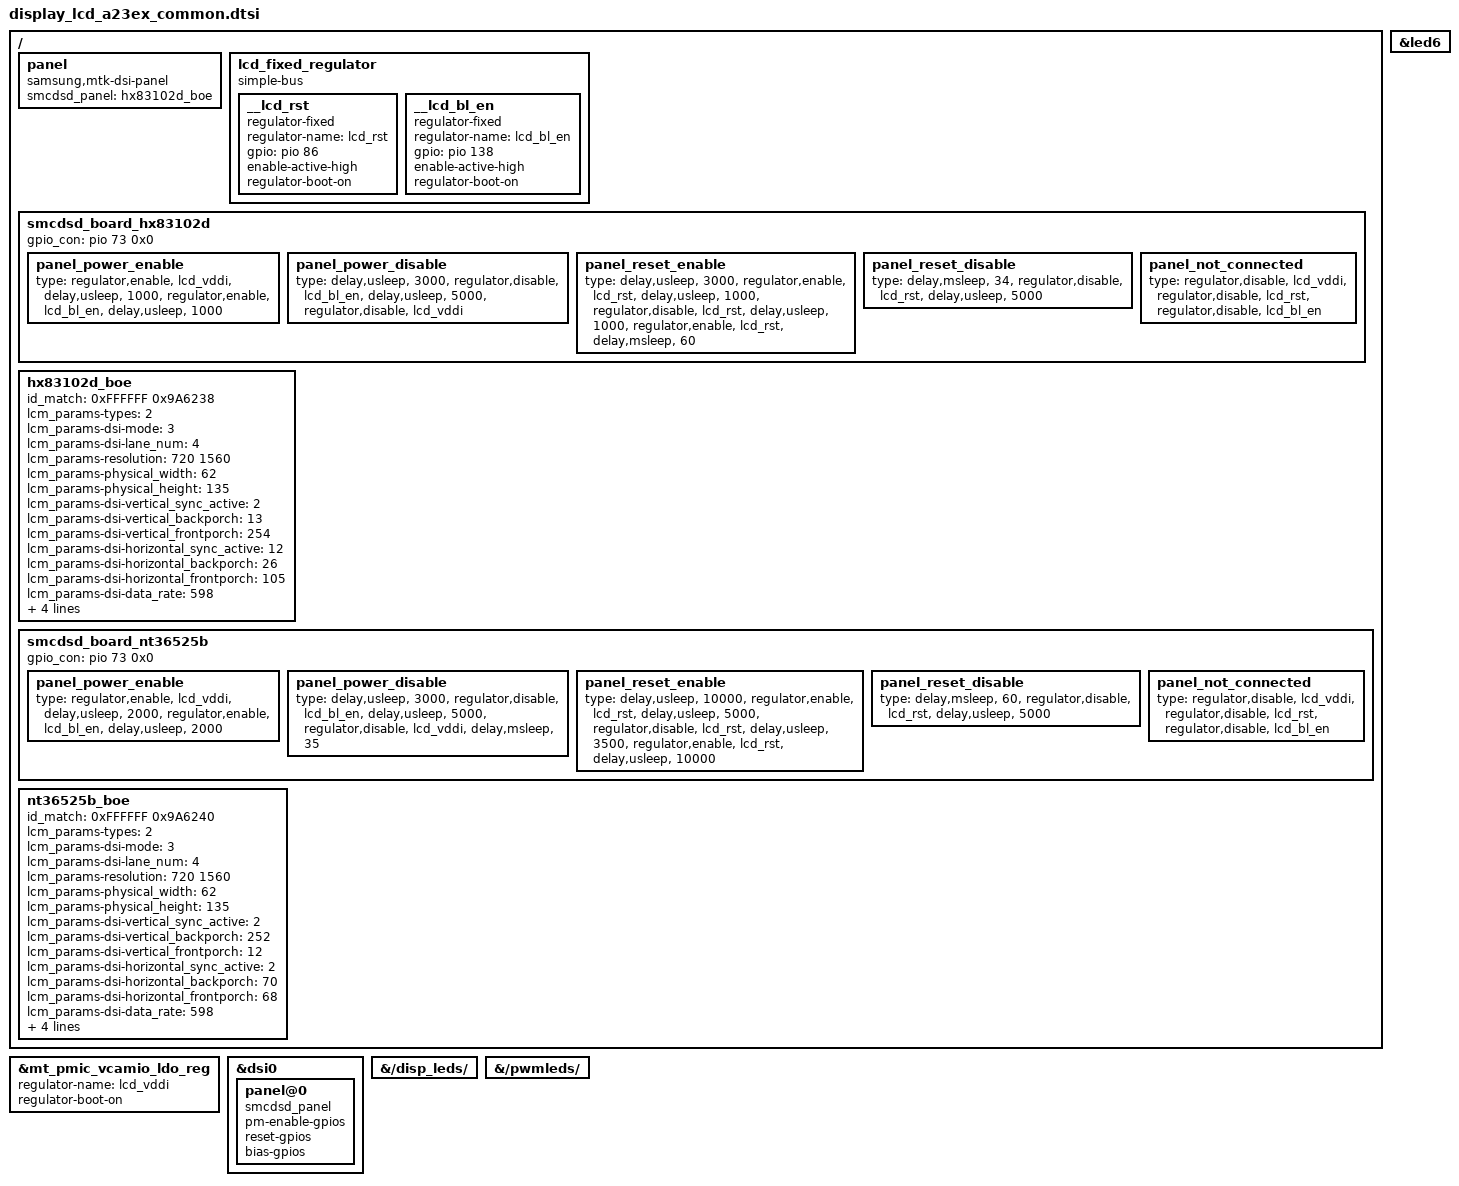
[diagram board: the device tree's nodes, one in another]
/*
 * SAMSUNG LCD Panel Device Tree Source
 *
 * Copyright (c) Samsung Electronics Co., Ltd.
 *		http://www.samsung.com
 *
 * This program is free software; you can redistribute it and/or modify
 * it under the terms of the GNU General Public License version 2 as
 * published by the Free Software Foundation.
 */

/ {
	fragment@led {
		target-path = "/disp_leds/";
		__overlay__ {
			compatible;
		};
	};

	fragment@pwm {
		target-path = "/pwmleds/";
		__overlay__ {
			compatible;
		};
	};

	fragment@lcd {
		target-path = "/";
		__overlay__ {
			panel {
				compatible = "samsung,mtk-dsi-panel";
				smcdsd_panel = <&hx83102d_boe>;
			};

			lcd_fixed_regulator: lcd_fixed_regulator {
				compatible = "simple-bus";

				__lcd_rst: __lcd_rst {
					compatible = "regulator-fixed";
					regulator-name = "lcd_rst";
					gpio = <&pio 86 0>;	/* LCD_RST */
					enable-active-high;
					regulator-boot-on;
				};
				__lcd_bl_en: __lcd_bl_en {
					compatible = "regulator-fixed";
					regulator-name = "lcd_bl_en";
					gpio = <&pio 138 0>;	/* LCD_BL_EN */
					enable-active-high;
					regulator-boot-on;
				};
			};

			smcdsd_board_hx83102d: smcdsd_board_hx83102d {
				//gpio_det = <&pio 6 0x1>;	/* LCD_BC_CTRL */
				gpio_con = <&pio 73 0x0>;	/* LCD_CON_DET */

				panel_power_enable {
					type =
					"regulator,enable",	"lcd_vddi",
					"delay,usleep",	"1000",
					"regulator,enable",	"lcd_bl_en",
					"delay,usleep",	"1000";
				};
				panel_power_disable {
					type =
					"delay,usleep",	"3000",
					"regulator,disable",	"lcd_bl_en",
					"delay,usleep",	"5000",
					"regulator,disable",	"lcd_vddi";
				};
				panel_reset_enable {
					type =
					"delay,usleep",	"3000",
					"regulator,enable",	"lcd_rst",
					"delay,usleep",	"1000",
					"regulator,disable",	"lcd_rst",
					"delay,usleep",	"1000",
					"regulator,enable",	"lcd_rst",
					"delay,msleep",	"60";
				};
				panel_reset_disable {
					type =
					"delay,msleep",	"34",
					"regulator,disable",	"lcd_rst",
					"delay,usleep",	"5000";
				};
				panel_not_connected {
					type =
					"regulator,disable",	"lcd_vddi",
					"regulator,disable",	"lcd_rst",
					"regulator,disable",	"lcd_bl_en";
				};
			};

			hx83102d_boe: hx83102d_boe {
				/* id_match: MASK(HEX) EXPECT(HEX) */
				id_match = <
					0xFFFFFF 0x9A6238	
				>;
				lcm_params-types = <2>; /* 0: LCM_TYPE_DBI, 1: LCM_TYPE_DPI, 2: LCM_TYPE_DSI */
				lcm_params-dsi-mode = <3>;	/* 0: CMD, 1: SYNC_PULSE_VDO, 2: SYNC_EVENT_VDO, 3: BURST_VDO */
				lcm_params-dsi-lane_num = <4>;

				lcm_params-resolution = <720 1560>;
				lcm_params-physical_width = <62>;		/* 62.1 x 134.55 */
				lcm_params-physical_height = <135>;

				lcm_params-dsi-vertical_sync_active = <2>;
				lcm_params-dsi-vertical_backporch = <13>;
				lcm_params-dsi-vertical_frontporch = <254>;
				lcm_params-dsi-horizontal_sync_active = <12>;
				lcm_params-dsi-horizontal_backporch = <26>;
				lcm_params-dsi-horizontal_frontporch = <105>;

				lcm_params-dsi-data_rate = <598>;
				lcm_params-dsi-ssc_disable = <1>;
				lcm_params-dsi-cont_clock = <1>;

				drm_params-vrefresh = <60>;

				smcdsd_board = <&smcdsd_board_hx83102d>;
			};

			smcdsd_board_nt36525b: smcdsd_board_nt36525b {
				//gpio_det = <&pio 6 0x1>;	/* LCD_BC_CTRL */
				gpio_con = <&pio 73 0x0>;	/* LCD_CON_DET */

				panel_power_enable {
					type =
					"regulator,enable",	"lcd_vddi",
					"delay,usleep",	"2000",
					"regulator,enable",	"lcd_bl_en",
					"delay,usleep",	"2000";
				};
				panel_power_disable {
					type =
					"delay,usleep",	"3000",
					"regulator,disable",	"lcd_bl_en",
					"delay,usleep",	"5000",
					"regulator,disable",	"lcd_vddi",
					"delay,msleep",	"35";
				};
				panel_reset_enable {
					type =
					"delay,usleep",	"10000",
					"regulator,enable",	"lcd_rst",
					"delay,usleep",	"5000",
					"regulator,disable",	"lcd_rst",
					"delay,usleep",	"3500",
					"regulator,enable",	"lcd_rst",
					"delay,usleep",	"10000";
				};
				panel_reset_disable {
					type =
					"delay,msleep",	"60",
					"regulator,disable",	"lcd_rst",
					"delay,usleep",	"5000";
				};
				panel_not_connected {
					type =
					"regulator,disable",	"lcd_vddi",
					"regulator,disable",	"lcd_rst",
					"regulator,disable",	"lcd_bl_en";
				};
			};

			nt36525b_boe: nt36525b_boe {
				/* id_match: MASK(HEX) EXPECT(HEX) */
				id_match = <
					0xFFFFFF 0x9A6240
				>;
				lcm_params-types = <2>; /* 0: LCM_TYPE_DBI, 1: LCM_TYPE_DPI, 2: LCM_TYPE_DSI */
				lcm_params-dsi-mode = <3>;	/* 0: CMD, 1: SYNC_PULSE_VDO, 2: SYNC_EVENT_VDO, 3: BURST_VDO */
				lcm_params-dsi-lane_num = <4>;

				lcm_params-resolution = <720 1560>;
				lcm_params-physical_width = <62>;		/* 62.10(H)mm x 134.55(V)mm */
				lcm_params-physical_height = <135>;

				lcm_params-dsi-vertical_sync_active = <2>;
				lcm_params-dsi-vertical_backporch = <252>;
				lcm_params-dsi-vertical_frontporch = <12>;
				lcm_params-dsi-horizontal_sync_active = <2>;
				lcm_params-dsi-horizontal_backporch = <70>;
				lcm_params-dsi-horizontal_frontporch = <68>;

				lcm_params-dsi-data_rate = <598>;
				lcm_params-dsi-ssc_disable = <1>;
				lcm_params-dsi-cont_clock = <1>;

				drm_params-vrefresh = <60>;

				smcdsd_board = <&smcdsd_board_nt36525b>;
			};
		};
	};
};

&mt_pmic_vcamio_ldo_reg {
	regulator-name = "lcd_vddi";
	regulator-boot-on;
};

&dsi0 {
	panel@0 {
		compatible = "smcdsd_panel";
		pm-enable-gpios;
		reset-gpios;
		bias-gpios;
	};
};

/* dts clean section */
&led6 {
	compatible;
};

